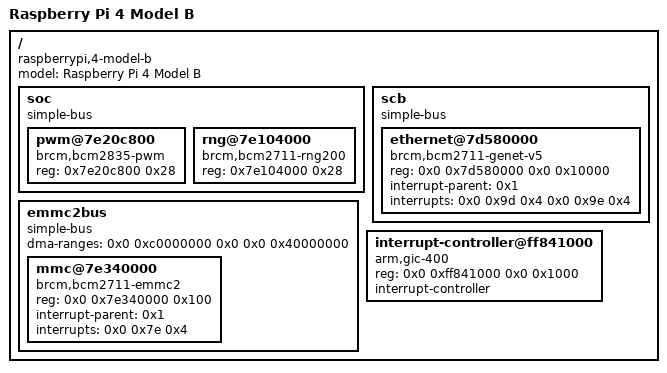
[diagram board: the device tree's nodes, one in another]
// SPDX-License-Identifier: BSD-3-Clause
// Generated by tests/fixtures/pi4-devd/generate.py; fixture pi4-devd-bad-ranges.
/dts-v1/;

/ {
    compatible = "raspberrypi,4-model-b", "brcm,bcm2711";
    model = "Raspberry Pi 4 Model B";
    #address-cells = <0x2>;
    #size-cells = <0x2>;
    soc {
        compatible = "simple-bus";
        #address-cells = <0x1>;
        #size-cells = <0x1>;
        ranges = <0x7e000000 0x0 0xfe000000 0x01800000>;
        pwm@7e20c800 {
            compatible = "brcm,bcm2835-pwm";
            reg = <0x7e20c800 0x28>;
            status = "okay";
        };
        rng@7e104000 {
            compatible = "brcm,bcm2711-rng200";
            reg = <0x7e104000 0x28>;
            status = "okay";
        };
    };
    scb {
        compatible = "simple-bus";
        #address-cells = <0x2>;
        #size-cells = <0x2>;
        ranges = <0x0 0x7d500000 0x0 0xfd500000 0x0 0x1100000>;
        ethernet@7d580000 {
            compatible = "brcm,bcm2711-genet-v5";
            reg = <0x0 0x7d580000 0x0 0x10000>;
            interrupt-parent = <0x1>;
            interrupts = <0x0 0x9d 0x4 0x0 0x9e 0x4>;
            status = "okay";
        };
    };
    emmc2bus {
        compatible = "simple-bus";
        #address-cells = <0x2>;
        #size-cells = <0x1>;
        ranges = <0x0 0x7e000000 0x0 0xfe000000 0x100000>;
        dma-ranges = <0x0 0xc0000000 0x0 0x0 0x40000000>;
        mmc@7e340000 {
            compatible = "brcm,bcm2711-emmc2";
            reg = <0x0 0x7e340000 0x100>;
            interrupt-parent = <0x1>;
            interrupts = <0x0 0x7e 0x4>;
            status = "okay";
        };
    };
    interrupt-controller@ff841000 {
        compatible = "arm,gic-400";
        reg = <0x0 0xff841000 0x0 0x1000>;
        interrupt-controller;
        #interrupt-cells = <0x3>;
        phandle = <0x1>;
    };
};
